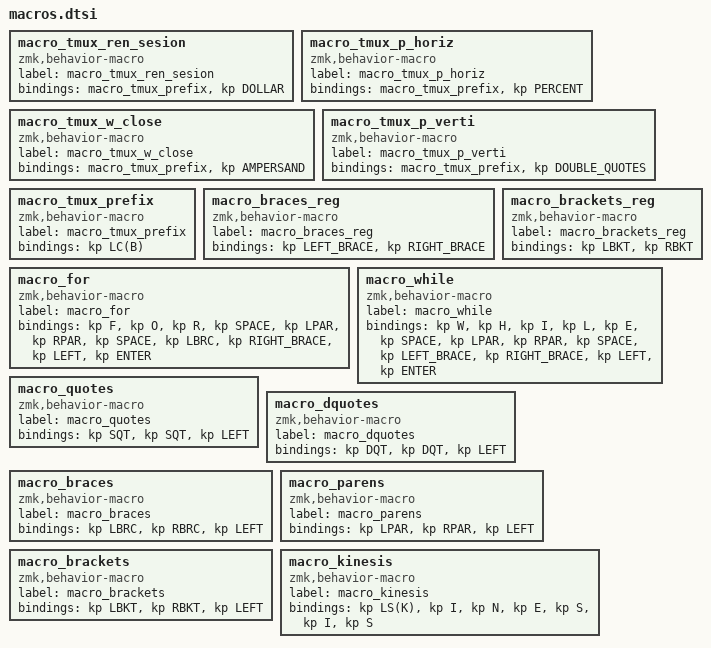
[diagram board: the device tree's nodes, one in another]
macro_tmux_ren_sesion: macro_tmux_ren_sesion{
compatible = "zmk,behavior-macro";
label = "macro_tmux_ren_sesion";
#binding-cells = <0>;
bindings = <&macro_tmux_prefix>, <&kp DOLLAR>;
};
macro_tmux_p_horiz: macro_tmux_p_horiz{
compatible = "zmk,behavior-macro";
label = "macro_tmux_p_horiz";
#binding-cells = <0>;
bindings = <&macro_tmux_prefix>, <&kp PERCENT>;
};
macro_tmux_w_close: macro_tmux_w_close{
compatible = "zmk,behavior-macro";
label = "macro_tmux_w_close";
#binding-cells = <0>;
bindings = <&macro_tmux_prefix>, <&kp AMPERSAND>;
};
macro_tmux_p_verti: macro_tmux_p_verti{
compatible = "zmk,behavior-macro";
label = "macro_tmux_p_verti";
#binding-cells = <0>;
bindings = <&macro_tmux_prefix>, <&kp DOUBLE_QUOTES>;
};
macro_tmux_prefix: macro_tmux_prefix{
compatible = "zmk,behavior-macro";
label = "macro_tmux_prefix";
#binding-cells = <0>;
bindings = <&kp LC(B)>;
};
macro_braces_reg: macro_braces_reg{
compatible = "zmk,behavior-macro";
label = "macro_braces_reg";
#binding-cells = <0>;
bindings = <&kp LEFT_BRACE>, <&kp RIGHT_BRACE>;
};
macro_brackets_reg: macro_brackets_reg{
compatible = "zmk,behavior-macro";
label = "macro_brackets_reg";
#binding-cells = <0>;
bindings = <&kp LBKT>, <&kp RBKT>;
};
macro_for: macro_for{
compatible = "zmk,behavior-macro";
label = "macro_for";
#binding-cells = <0>;
bindings = <&kp F>, <&kp O>, <&kp R>, <&kp SPACE>, <&kp LPAR>, <&kp RPAR>, <&kp SPACE>, <&kp LBRC>, <&kp RIGHT_BRACE>, <&kp LEFT>, <&kp ENTER>;
};
macro_while: macro_while{
compatible = "zmk,behavior-macro";
label = "macro_while";
#binding-cells = <0>;
bindings = <&kp W>, <&kp H>, <&kp I>, <&kp L>, <&kp E>, <&kp SPACE>, <&kp LPAR>, <&kp RPAR>, <&kp SPACE>, <&kp LEFT_BRACE>, <&kp RIGHT_BRACE>, <&kp LEFT>, <&kp ENTER>;
};
macro_quotes: macro_quotes{
compatible = "zmk,behavior-macro";
label = "macro_quotes";
#binding-cells = <0>;
bindings = <&kp SQT>, <&kp SQT>, <&kp LEFT>;
};
macro_dquotes: macro_dquotes{
compatible = "zmk,behavior-macro";
label = "macro_dquotes";
#binding-cells = <0>;
bindings = <&kp DQT>, <&kp DQT>, <&kp LEFT>;
};
macro_braces: macro_braces{
compatible = "zmk,behavior-macro";
label = "macro_braces";
#binding-cells = <0>;
bindings = <&kp LBRC>, <&kp RBRC>, <&kp LEFT>;
};
macro_parens: macro_parens{
compatible = "zmk,behavior-macro";
label = "macro_parens";
#binding-cells = <0>;
bindings = <&kp LPAR>, <&kp RPAR>, <&kp LEFT>;
};
macro_brackets: macro_brackets{
compatible = "zmk,behavior-macro";
label = "macro_brackets";
#binding-cells = <0>;
bindings = <&kp LBKT>, <&kp RBKT>, <&kp LEFT>;
};
macro_kinesis: macro_kinesis{
compatible = "zmk,behavior-macro";
label = "macro_kinesis";
#binding-cells = <0>;
bindings = <&kp LS(K)>, <&kp I>, <&kp N>, <&kp E>, <&kp S>, <&kp I>, <&kp S>;
};
